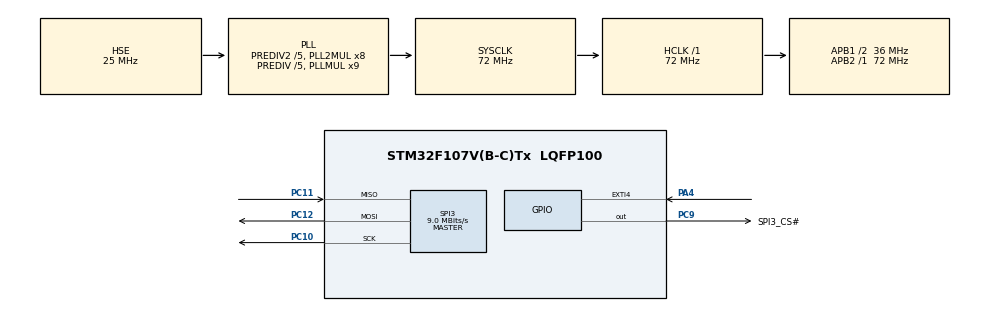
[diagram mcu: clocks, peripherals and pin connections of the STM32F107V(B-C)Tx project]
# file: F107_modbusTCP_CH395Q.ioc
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Mcu.Family=STM32F1
Mcu.Name=STM32F107V(B-C)Tx
Mcu.Package=LQFP100
NVIC.EXTI4_IRQn=true\:0\:0\:false\:false\:true\:true\:true
NVIC.PriorityGroup=NVIC_PRIORITYGROUP_4
NVIC.TIM7_IRQn=true\:0\:0\:false\:false\:true\:false\:true
NVIC.TimeBase=TIM7_IRQn
NVIC.TimeBaseIP=TIM7
OSC_IN.Mode=HSE-External-Oscillator
OSC_IN.Signal=RCC_OSC_IN
OSC_OUT.Mode=HSE-External-Oscillator
OSC_OUT.Signal=RCC_OSC_OUT
PA13.Mode=Serial_Wire
PA13.Signal=SYS_JTMS-SWDIO
PA14.Mode=Serial_Wire
PA14.Signal=SYS_JTCK-SWCLK
PA4.GPIO_ModeDefaultEXTI=GPIO_MODE_IT_FALLING
PA4.Signal=GPXTI4
PC10.Mode=Full_Duplex_Master
PC10.Signal=SPI3_SCK
PC11.Mode=Full_Duplex_Master
PC11.Signal=SPI3_MISO
PC12.Mode=Full_Duplex_Master
PC12.Signal=SPI3_MOSI
PC9.GPIO_Label=SPI3_CS\#
PC9.GPIO_PuPd=GPIO_PULLUP
PC9.Signal=GPIO_Output
ProjectManager.HeapSize=0x50
ProjectManager.StackSize=0x1000
ProjectManager.TargetToolchain=MDK-ARM V5.27
RCC.AHBFreq_Value=72000000
RCC.APB1CLKDivider=RCC_HCLK_DIV2
RCC.APB1Freq_Value=36000000
RCC.APB1TimFreq_Value=72000000
RCC.APB2Freq_Value=72000000
RCC.APB2TimFreq_Value=72000000
RCC.HCLKFreq_Value=72000000
RCC.HSEDivPLL=RCC_HSE_PREDIV_DIV5
RCC.HSE_VALUE=25000000
RCC.PLLMUL=RCC_PLL_MUL9
RCC.PLLSourceVirtual=RCC_PLLSOURCE_HSE
RCC.Prediv1Source=RCC_PREDIV1_SOURCE_PLL2
RCC.Prediv2=RCC_HSE_PREDIV2_DIV5
RCC.SYSCLKFreq_VALUE=72000000
RCC.SYSCLKSource=RCC_SYSCLKSOURCE_PLLCLK
RCC.USBFreq_Value=48000000
SPI3.BaudRatePrescaler=SPI_BAUDRATEPRESCALER_4
SPI3.CLKPhase=SPI_PHASE_1EDGE
SPI3.CalculateBaudRate=9.0 MBits/s
SPI3.Direction=SPI_DIRECTION_2LINES
SPI3.Mode=SPI_MODE_MASTER
SPI3.VirtualType=VM_MASTER
VP_SYS_VS_tim7.Mode=TIM7
board=custom

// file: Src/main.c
/* USER CODE BEGIN Header */
/**
  ******************************************************************************
  * @file           : main.c
  * @brief          : Main program body
  ******************************************************************************
  * @attention
  *
  * <h2><center>&copy; Copyright (c) 2021 STMicroelectronics.
  * All rights reserved.</center></h2>
  *
  * This software component is licensed by ST under BSD 3-Clause license,
  * the "License"; You may not use this file except in compliance with the
  * License. You may obtain a copy of the License at:
  *                        opensource.org/licenses/BSD-3-Clause
  *
  ******************************************************************************
  */
/* USER CODE END Header */
#include "main.h"
#include "spi.h"
#include "gpio.h"

/* USER CODE BEGIN Includes */
#include "../user_bsp/ch395/ch395cmd.h"
/* USER CODE END Includes */

/* USER CODE BEGIN PM */
uint8_t i,retval;
/* USER CODE END PM */

void SystemClock_Config(void);

/* USER CODE BEGIN 0 */
extern SOCKET_HandleTypedef  Socket_0;
extern CH395_HandleTypedef  ch395_0;
/* USER CODE END 0 */

int main(void)
{

  /* MCU Configuration--------------------------------------------------------*/

  /* Reset of all peripherals, Initializes the Flash interface and the Systick. */
  HAL_Init();

  /* Configure the system clock */
  SystemClock_Config();

  /* Initialize all configured peripherals */
  MX_GPIO_Init();
  MX_SPI3_Init();
  /* USER CODE BEGIN 2 */

    //------------------------------------//
    //初始化395芯片
    CH395_Init(&ch395_0,&Socket_0);
    //------------------------------------//

    //查询CH395PHY未连接
    while(CH395CMDGetPHYStatus(&ch395_0) == PHY_DISCONN)
    {
        HAL_Delay(200);
    }

    //------------------------------------//
    //初始化socket
    CH395_InitSocketParam(&ch395_0,&Socket_0);
    //------------------------------------//

  /* USER CODE END 2 */

  /* Infinite loop */
    while (1)
    {

    }
}

void SystemClock_Config(void)
{
  RCC_OscInitTypeDef RCC_OscInitStruct = {0};
  RCC_ClkInitTypeDef RCC_ClkInitStruct = {0};

  /** Initializes the RCC Oscillators according to the specified parameters
  * in the RCC_OscInitTypeDef structure.
  */
  RCC_OscInitStruct.OscillatorType = RCC_OSCILLATORTYPE_HSE;
  RCC_OscInitStruct.HSEState = RCC_HSE_ON;
  RCC_OscInitStruct.HSEPredivValue = RCC_HSE_PREDIV_DIV5;
  RCC_OscInitStruct.HSIState = RCC_HSI_ON;
  RCC_OscInitStruct.Prediv1Source = RCC_PREDIV1_SOURCE_PLL2;
  RCC_OscInitStruct.PLL.PLLState = RCC_PLL_ON;
  RCC_OscInitStruct.PLL.PLLSource = RCC_PLLSOURCE_HSE;
  RCC_OscInitStruct.PLL.PLLMUL = RCC_PLL_MUL9;
  RCC_OscInitStruct.PLL2.PLL2State = RCC_PLL2_ON;
  RCC_OscInitStruct.PLL2.PLL2MUL = RCC_PLL2_MUL8;
  RCC_OscInitStruct.PLL2.HSEPrediv2Value = RCC_HSE_PREDIV2_DIV5;
  if (HAL_RCC_OscConfig(&RCC_OscInitStruct) != HAL_OK)
  {
    Error_Handler();
  }
  /** Initializes the CPU, AHB and APB buses clocks
  */
  RCC_ClkInitStruct.ClockType = RCC_CLOCKTYPE_HCLK|RCC_CLOCKTYPE_SYSCLK
                              |RCC_CLOCKTYPE_PCLK1|RCC_CLOCKTYPE_PCLK2;
  RCC_ClkInitStruct.SYSCLKSource = RCC_SYSCLKSOURCE_PLLCLK;
  RCC_ClkInitStruct.AHBCLKDivider = RCC_SYSCLK_DIV1;
  RCC_ClkInitStruct.APB1CLKDivider = RCC_HCLK_DIV2;
  RCC_ClkInitStruct.APB2CLKDivider = RCC_HCLK_DIV1;

  if (HAL_RCC_ClockConfig(&RCC_ClkInitStruct, FLASH_LATENCY_2) != HAL_OK)
  {
    Error_Handler();
  }
  /** Configure the Systick interrupt time
  */
  __HAL_RCC_PLLI2S_ENABLE();
}

/* USER CODE BEGIN 4 */
//按键中断回调
void HAL_GPIO_EXTI_Callback(uint16_t GPIO_Pin)
{
    if(GPIO_Pin == ch395_0.INT_PIN)
    {
        CH395_SocketIRQ(&ch395_0,&Socket_0);
    }
}
/* USER CODE END 4 */

 /**
  * @brief  Period elapsed callback in non blocking mode
  * @note   This function is called  when TIM7 interrupt took place, inside
  * HAL_TIM_IRQHandler(). It makes a direct call to HAL_IncTick() to increment
  * a global variable "uwTick" used as application time base.
  * @param  htim : TIM handle
  * @retval None
  */
void HAL_TIM_PeriodElapsedCallback(TIM_HandleTypeDef *htim)
{
  if (htim->Instance == TIM7) {
    HAL_IncTick();
  }
}

void Error_Handler(void)
{
    __disable_irq();
    while (1)
    {
    }
}

/************************ (C) COPYRIGHT STMicroelectronics *****END OF FILE****/
